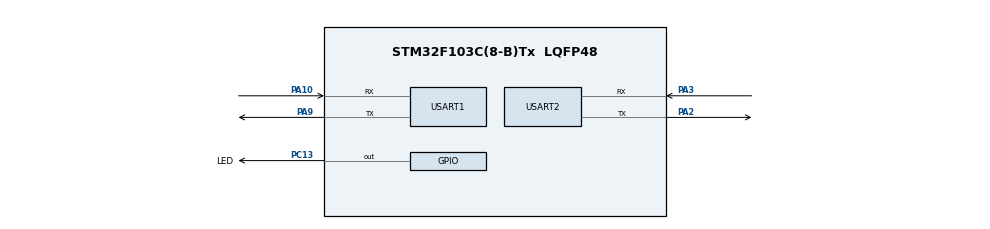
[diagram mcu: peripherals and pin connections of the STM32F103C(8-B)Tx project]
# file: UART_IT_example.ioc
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Mcu.Family=STM32F1
Mcu.Name=STM32F103C(8-B)Tx
Mcu.Package=LQFP48
NVIC.PriorityGroup=NVIC_PRIORITYGROUP_4
NVIC.USART1_IRQn=true\:0\:0\:false\:false\:true\:true\:true\:true
NVIC.USART2_IRQn=true\:0\:0\:false\:false\:true\:true\:true\:true
PA10.Mode=Asynchronous
PA10.Signal=USART1_RX
PA2.Mode=Asynchronous
PA2.Signal=USART2_TX
PA3.Mode=Asynchronous
PA3.Signal=USART2_RX
PA9.Mode=Asynchronous
PA9.Signal=USART1_TX
PC13-TAMPER-RTC.GPIO_Label=LED
PC13-TAMPER-RTC.Signal=GPIO_Output
PD0-OSC_IN.Mode=HSE-External-Oscillator
PD0-OSC_IN.Signal=RCC_OSC_IN
PD1-OSC_OUT.Mode=HSE-External-Oscillator
PD1-OSC_OUT.Signal=RCC_OSC_OUT
ProjectManager.HeapSize=0x200
ProjectManager.StackSize=0x400
ProjectManager.TargetToolchain=STM32CubeIDE
RCC.APB1Freq_Value=8000000
RCC.APB2Freq_Value=8000000
USART1.VirtualMode=VM_ASYNC
USART2.VirtualMode=VM_ASYNC
board=custom

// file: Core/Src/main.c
/* USER CODE BEGIN Header */
/**
  ******************************************************************************
  * @file           : main.c
  * @brief          : Main program body
  ******************************************************************************
  * @attention
  *
  * Copyright (c) 2023 STMicroelectronics.
  * All rights reserved.
  *
  * This software is licensed under terms that can be found in the LICENSE file
  * in the root directory of this software component.
  * If no LICENSE file comes with this software, it is provided AS-IS.
  *
  ******************************************************************************
  */
/* USER CODE END Header */
#include "main.h"

/* USER CODE BEGIN Includes */

// Начало пояснений в разделе "USER CODE BEGIN PV" <<<<<<<<<<<<<<<<<<<<<<<<<<<<<<<<<<<<<<<<<<<<<<<<<<<<<<<< //

#include <stdio.h>

/* USER CODE END Includes */

UART_HandleTypeDef huart1;
UART_HandleTypeDef huart2;

/* USER CODE BEGIN PV */

// Название этой области расшифровывается как Private Variables, тут объявляем переменные

uint8_t uart1_tx_var = 125;			// Переменная, которую нужно передать UART1 -> UART2
uint8_t uart2_rx_var = 0;			// Переменная для приема в UART2

uint8_t uart2_tx_buff[5] = {0,};	// Буффер для передачи данных UART2 -> PC

// Продолжение в USER CODE BEGIN 3

/* USER CODE END PV */

void SystemClock_Config(void);
static void MX_GPIO_Init(void);
static void MX_USART1_UART_Init(void);
static void MX_USART2_UART_Init(void);

int main(void)
{

  /* MCU Configuration--------------------------------------------------------*/

  /* Reset of all peripherals, Initializes the Flash interface and the Systick. */
  HAL_Init();

  /* Configure the system clock */
  SystemClock_Config();

  /* Initialize all configured peripherals */
  MX_GPIO_Init();
  MX_USART1_UART_Init();
  MX_USART2_UART_Init();

  /* Infinite loop */
  while (1)
  {

    /* USER CODE BEGIN 3 */

	  // Начало пояснений в разделе "USER CODE BEGIN PV"

	  // Запускаем прием на UART2, чтобы быть готовым ловить посылку с UART1
	  HAL_UART_Receive_IT(&huart2, &uart2_rx_var, 1);

	  // Передаем нашу переменную на UART2
	  // Дальнейшие действия описаны в области "USER CODE BEGIN 4", они
	  // связаны с обработкой прерываний
	  HAL_UART_Transmit_IT(&huart1, &uart1_tx_var, 1);

	  HAL_Delay(200);
  }
  /* USER CODE END 3 */
}

void SystemClock_Config(void)
{
  RCC_OscInitTypeDef RCC_OscInitStruct = {0};
  RCC_ClkInitTypeDef RCC_ClkInitStruct = {0};

  /** Initializes the RCC Oscillators according to the specified parameters
  * in the RCC_OscInitTypeDef structure.
  */
  RCC_OscInitStruct.OscillatorType = RCC_OSCILLATORTYPE_HSI;
  RCC_OscInitStruct.HSIState = RCC_HSI_ON;
  RCC_OscInitStruct.HSICalibrationValue = RCC_HSICALIBRATION_DEFAULT;
  RCC_OscInitStruct.PLL.PLLState = RCC_PLL_NONE;
  if (HAL_RCC_OscConfig(&RCC_OscInitStruct) != HAL_OK)
  {
    Error_Handler();
  }

  /** Initializes the CPU, AHB and APB buses clocks
  */
  RCC_ClkInitStruct.ClockType = RCC_CLOCKTYPE_HCLK|RCC_CLOCKTYPE_SYSCLK
                              |RCC_CLOCKTYPE_PCLK1|RCC_CLOCKTYPE_PCLK2;
  RCC_ClkInitStruct.SYSCLKSource = RCC_SYSCLKSOURCE_HSI;
  RCC_ClkInitStruct.AHBCLKDivider = RCC_SYSCLK_DIV1;
  RCC_ClkInitStruct.APB1CLKDivider = RCC_HCLK_DIV1;
  RCC_ClkInitStruct.APB2CLKDivider = RCC_HCLK_DIV1;

  if (HAL_RCC_ClockConfig(&RCC_ClkInitStruct, FLASH_LATENCY_0) != HAL_OK)
  {
    Error_Handler();
  }
}

static void MX_USART1_UART_Init(void)
{

  huart1.Instance = USART1;
  huart1.Init.BaudRate = 115200;
  huart1.Init.WordLength = UART_WORDLENGTH_8B;
  huart1.Init.StopBits = UART_STOPBITS_1;
  huart1.Init.Parity = UART_PARITY_NONE;
  huart1.Init.Mode = UART_MODE_TX_RX;
  huart1.Init.HwFlowCtl = UART_HWCONTROL_NONE;
  huart1.Init.OverSampling = UART_OVERSAMPLING_16;
  if (HAL_UART_Init(&huart1) != HAL_OK)
  {
    Error_Handler();
  }

}

static void MX_USART2_UART_Init(void)
{

  huart2.Instance = USART2;
  huart2.Init.BaudRate = 115200;
  huart2.Init.WordLength = UART_WORDLENGTH_8B;
  huart2.Init.StopBits = UART_STOPBITS_1;
  huart2.Init.Parity = UART_PARITY_NONE;
  huart2.Init.Mode = UART_MODE_TX_RX;
  huart2.Init.HwFlowCtl = UART_HWCONTROL_NONE;
  huart2.Init.OverSampling = UART_OVERSAMPLING_16;
  if (HAL_UART_Init(&huart2) != HAL_OK)
  {
    Error_Handler();
  }

}

static void MX_GPIO_Init(void)
{
  GPIO_InitTypeDef GPIO_InitStruct = {0};

  /* GPIO Ports Clock Enable */
  __HAL_RCC_GPIOC_CLK_ENABLE();
  __HAL_RCC_GPIOD_CLK_ENABLE();
  __HAL_RCC_GPIOA_CLK_ENABLE();

  /*Configure GPIO pin Output Level */
  HAL_GPIO_WritePin(LED_GPIO_Port, LED_Pin, GPIO_PIN_RESET);

  /*Configure GPIO pin : LED_Pin */
  GPIO_InitStruct.Pin = LED_Pin;
  GPIO_InitStruct.Mode = GPIO_MODE_OUTPUT_PP;
  GPIO_InitStruct.Pull = GPIO_NOPULL;
  GPIO_InitStruct.Speed = GPIO_SPEED_FREQ_LOW;
  HAL_GPIO_Init(LED_GPIO_Port, &GPIO_InitStruct);

}

/* USER CODE BEGIN 4 */

/*
 * CallBack по окончанию передачи посылки через UART
 *
 * Он должен быть пустым (тут ничего кроме светодиода), просто, чтобы было видно, что CallBack'и
 * можго обрабатывать разные для одной и той же периферии, в зависимости от
 * требуемого события
 */
void HAL_UART_TxCpltCallback(UART_HandleTypeDef *huart){

}

/*
 * CallBack по окончанию приема посылки через UART
 */
void HAL_UART_RxCpltCallback(UART_HandleTypeDef *huart){
	if(huart->Instance == USART2){
		/*
		 * Почему мы не можем просто передать число на ПК без преобразований,
		 * чтобы оно отобразилось в консоли?
		 *
		 * Дело в том, что каждая цифра которая отображается на консоли является отдельной переменной.
		 * Значение каждой такой переменной отображает код символа в ASCII коде
		 * (загуглите "ASCII code table", чтобы было понятнее).
		 * Так если вы хотите передать число 211, вам недостаточно передать одну переменную, нужно
		 * передать массив, который будет содержать 3 переменных в каждой из которых записан соответстующий
		 * код для каждого из символов, для 211 массив будет выглядеть так: {0x32, 0x31, 0x31}.
		 * Приставка 0x - означает, что число записанно в шестнадцатиричной системе.
		 *
		 * Функция sprintf позволяет преобразовать нашу переменную в набор символов из ASCII кода.
		 * Важный момент, поскольку эта функция является частью библиотеки, её нужно подключить перед всем
		 * остальным кодом, подключение можете увидеть в самом верху этого фала, строчка выглядит так:
		 *     #include <stdio.h>
		 * о работе функции можно узнать загуглив её название.
		 */

		sprintf((char *)uart2_tx_buff, "%d\r\n", uart2_rx_var);

		/*
		 * После того, как было произведено преобразование можем передать нашу переменную
		 */

		HAL_UART_Transmit(&huart2, uart2_tx_buff, 5, 100);
	}
}
/* USER CODE END 4 */

void Error_Handler(void)
{
  __disable_irq();
  while (1)
  {
  }
}
